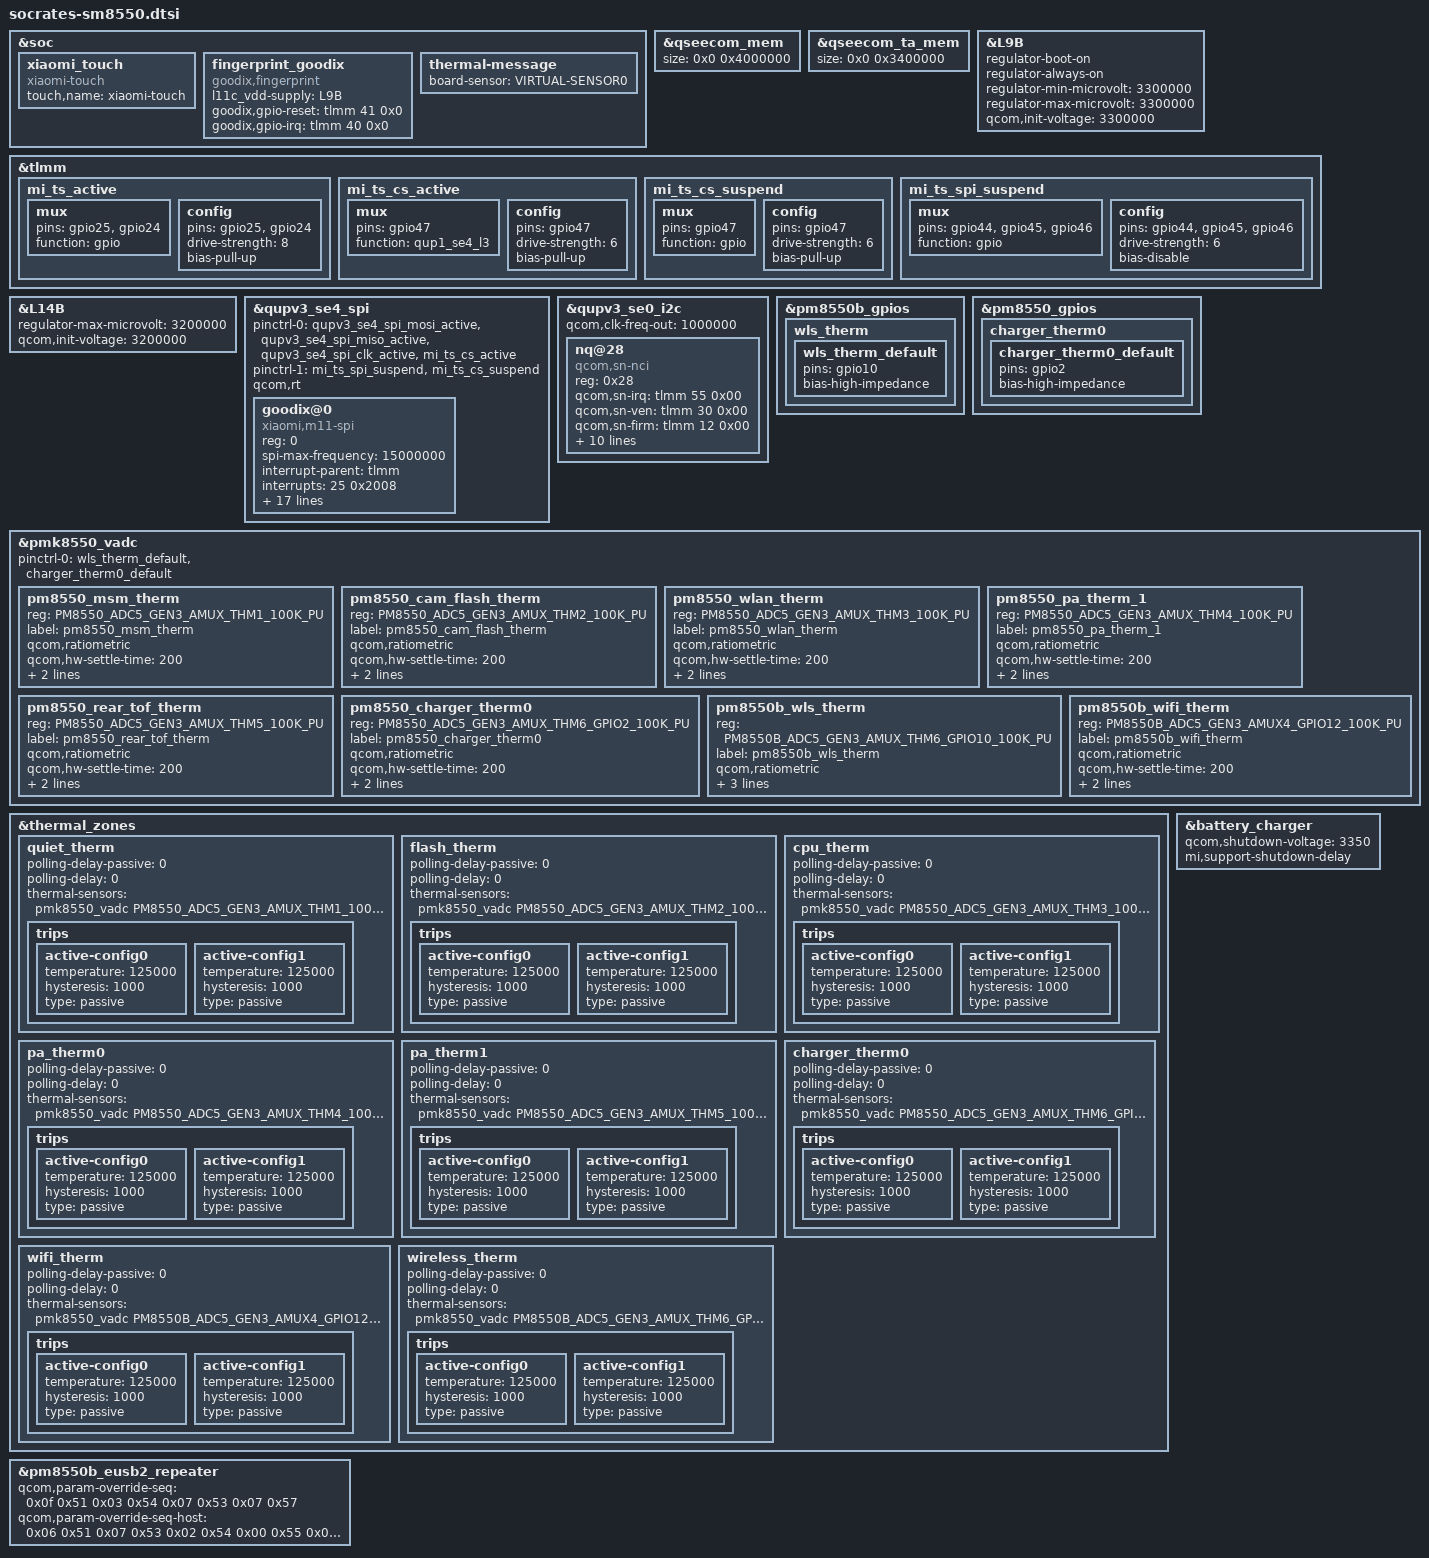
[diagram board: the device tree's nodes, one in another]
/*
  this file is for attribution only of socrates
  And public attribution of xiaomi platforms(like M2 and so and)
*/

#define SOCRATES_REGULATOR_OCP
#include "socrates-pinctrl.dtsi"
#include "xiaomi-sm8550-common.dtsi"
#include <dt-bindings/clock/qcom,rpmh.h>

&soc {
	xiaomi_touch {
		compatible = "xiaomi-touch";
		status = "ok";
		touch,name = "xiaomi-touch";
	};
	fingerprint_goodix {
		compatible = "goodix,fingerprint";
		l11c_vdd-supply = <&L9B>;
		goodix,gpio-reset = <&tlmm 41 0x0>;
		goodix,gpio-irq = <&tlmm 40 0x0>;
		status = "ok";
	};
};

&qseecom_mem {
		size = <0x0 0x4000000>;
};

&qseecom_ta_mem {
		size = <0x0 0x3400000>;
};

&L9B {
	regulator-boot-on;
	regulator-always-on;
	regulator-min-microvolt = <3300000>;
	regulator-max-microvolt = <3300000>;
	qcom,init-voltage = <3300000>;
};

&tlmm {
	mi_ts_active: mi_ts_active {
		mux {
				pins = "gpio25", "gpio24";
				function = "gpio";
		};

		config {
				pins = "gpio25", "gpio24";
				drive-strength = <8>;
				bias-pull-up;
		};
	};

	mi_ts_cs_active: mi_ts_cs_active {
		mux {
			pins = "gpio47";
			function = "qup1_se4_l3";
		};

		config {
			pins = "gpio47";
			drive-strength = <6>;
			bias-pull-up;
		};
	};

	mi_ts_cs_suspend: mi_ts_cs_suspend {
		mux {
			pins = "gpio47";
			function = "gpio";
		};

		config {
			pins = "gpio47";
			drive-strength = <6>;
			bias-pull-up;
		};
	};

	mi_ts_spi_suspend: mi_ts_spi_suspend {
		mux {
			pins = "gpio44", "gpio45", "gpio46";
			function = "gpio";
		};

		config {
			pins = "gpio44", "gpio45", "gpio46";
			drive-strength = <6>;
			bias-disable;
		};
	};
};

&L14B {
	regulator-max-microvolt = <3200000>;
	qcom,init-voltage = <3200000>;
};

&qupv3_se4_spi {
	status = "ok";
	pinctrl-0 = <&qupv3_se4_spi_mosi_active>, <&qupv3_se4_spi_miso_active>,
 						<&qupv3_se4_spi_clk_active>, <&mi_ts_cs_active>;
	pinctrl-1 = <&mi_ts_spi_suspend &mi_ts_cs_suspend>;
	qcom,rt;
	goodix@0 {
		status = "ok";
		compatible = "xiaomi,m11-spi";
		reg = <0>;
		spi-max-frequency = <15000000>;
		interrupt-parent = <&tlmm>;
		interrupts = <25 0x2008>;
		goodix,avdd-name = "avdd";
		avdd-supply = <&L14B>;
		pinctrl-names = "pmx_ts_active", "pmx_ts_suspend";
		pinctrl-0 = <&mi_ts_active>;
		pinctrl-1 = <&ts_int_suspend &ts_reset_suspend>;

		//goodix,avdd-gpio = <&tlmm 71 0x0>;
		goodix,iovdd-name = "vdd";
		vdd-supply = <&L12B>;
		goodix,irq-gpio = <&tlmm 25 0x2008>;
		goodix,reset-gpio = <&tlmm 24 0x00>;
		goodix,irq-flags = <2>;
		goodix,panel-max-x = <14400>;
		goodix,panel-max-y = <32000>;
		goodix,panel-max-w = <255>;
		goodix,panel-max-p = <4096>;
		goodix,firmware-name = "goodix_firmware_m11";
		goodix,config-name = "goodix_cfg_group_m11";
		goodix,touch-expert-array = <2 3 2 2
					     4 3 3 2
					     3 3 4 2>;
	};
};

&qupv3_se0_i2c {
	status = "ok";
	qcom,clk-freq-out = <1000000>;
	#address-cells = <1>;
	#size-cells = <0>;
	nq@28 {
		compatible = "qcom,sn-nci";
		reg = <0x28>;
		qcom,sn-irq = <&tlmm 55 0x00>;
		qcom,sn-ven = <&tlmm 30 0x00>;
		qcom,sn-firm = <&tlmm 12 0x00>;
		qcom,sn-clkreq = <&tlmm 31 0x00>;
		qcom,sn-szone = "enable";
		qcom,sn-vdd-1p8-supply = <&L15B>;
		qcom,sn-vdd-1p8-voltage = <1760000 1800000>;
		qcom,sn-vdd-1p8-current = <157000>;
		interrupt-parent = <&tlmm>;
		interrupts = <55 0>;
		interrupt-names = "nfc_irq";
		pinctrl-names = "nfc_active", "nfc_suspend";
		pinctrl-0 = <&nfc_int_active &nfc_enable_active>;
		pinctrl-1 = <&nfc_int_suspend &nfc_enable_suspend>;
		/*below clocks only need for Kailua V1 device */
		clocks = <&rpmhcc RPMH_LN_BB_CLK2>;
		clock-names = "nfc_ref_clk";
	};
};

&pm8550b_gpios {
	wls_therm {
		wls_therm_default: wls_therm_default {
		pins = "gpio10";
		bias-high-impedance;
	};
	};
};

&pm8550_gpios {
	charger_therm0 {
		charger_therm0_default: charger_therm0_default {
		pins = "gpio2";
		bias-high-impedance;
	};
	};
};

&pmk8550_vadc {
	pinctrl-names = "default";
	pinctrl-0 = <&wls_therm_default>, <&charger_therm0_default>;
	pm8550_msm_therm {
		reg = <PM8550_ADC5_GEN3_AMUX_THM1_100K_PU>;
		label = "pm8550_msm_therm";
		qcom,ratiometric;
		qcom,hw-settle-time = <200>;
		qcom,pre-scaling = <1 1>;
		qcom,adc-tm-type = <1>;
	};

	pm8550_cam_flash_therm {
		reg = <PM8550_ADC5_GEN3_AMUX_THM2_100K_PU>;
		label = "pm8550_cam_flash_therm";
		qcom,ratiometric;
		qcom,hw-settle-time = <200>;
		qcom,pre-scaling = <1 1>;
		qcom,adc-tm-type = <1>;
	};

	pm8550_wlan_therm {
		reg = <PM8550_ADC5_GEN3_AMUX_THM3_100K_PU>;
		label = "pm8550_wlan_therm";
		qcom,ratiometric;
		qcom,hw-settle-time = <200>;
		qcom,pre-scaling = <1 1>;
		qcom,adc-tm-type = <1>;
	};

	pm8550_pa_therm_1 {
		reg = <PM8550_ADC5_GEN3_AMUX_THM4_100K_PU>;
		label = "pm8550_pa_therm_1";
		qcom,ratiometric;
		qcom,hw-settle-time = <200>;
		qcom,pre-scaling = <1 1>;
		qcom,adc-tm-type = <1>;
	};

	pm8550_rear_tof_therm {
		reg = <PM8550_ADC5_GEN3_AMUX_THM5_100K_PU>;
		label = "pm8550_rear_tof_therm";
		qcom,ratiometric;
		qcom,hw-settle-time = <200>;
		qcom,pre-scaling = <1 1>;
		qcom,adc-tm-type = <1>;
	};

	pm8550_charger_therm0 {
		reg = <PM8550_ADC5_GEN3_AMUX_THM6_GPIO2_100K_PU>;
		label = "pm8550_charger_therm0";
		qcom,ratiometric;
		qcom,hw-settle-time = <200>;
		qcom,pre-scaling = <1 1>;
		qcom,adc-tm-type = <1>;
	};

	pm8550b_wls_therm {
		reg = <PM8550B_ADC5_GEN3_AMUX_THM6_GPIO10_100K_PU>;
		label = "pm8550b_wls_therm";
		qcom,ratiometric;
		qcom,hw-settle-time = <200>;
		qcom,pre-scaling = <1 1>;
		qcom,adc-tm-type = <1>;
	};

	pm8550b_wifi_therm {
		reg = <PM8550B_ADC5_GEN3_AMUX4_GPIO12_100K_PU>;
		label = "pm8550b_wifi_therm";
		qcom,ratiometric;
		qcom,hw-settle-time = <200>;
		qcom,pre-scaling = <1 1>;
		qcom,adc-tm-type = <1>;
	};
};

&thermal_zones {
	quiet_therm {
		polling-delay-passive = <0>;
		polling-delay = <0>;
		thermal-sensors = <&pmk8550_vadc PM8550_ADC5_GEN3_AMUX_THM1_100K_PU>;
		trips {
			active-config0 {
				temperature = <125000>;
				hysteresis = <1000>;
				type = "passive";
			};

			active-config1 {
				temperature = <125000>;
				hysteresis = <1000>;
				type = "passive";
			};
		};
	};

	flash_therm {
		polling-delay-passive = <0>;
		polling-delay = <0>;
		thermal-sensors = <&pmk8550_vadc PM8550_ADC5_GEN3_AMUX_THM2_100K_PU>;
		trips {
			active-config0 {
				temperature = <125000>;
				hysteresis = <1000>;
				type = "passive";
			};

			active-config1 {
				temperature = <125000>;
				hysteresis = <1000>;
				type = "passive";
			};
		};
	};

	cpu_therm {
		polling-delay-passive = <0>;
		polling-delay = <0>;
		thermal-sensors = <&pmk8550_vadc PM8550_ADC5_GEN3_AMUX_THM3_100K_PU>;
		trips {
			active-config0 {
				temperature = <125000>;
				hysteresis = <1000>;
				type = "passive";
			};

			active-config1 {
				temperature = <125000>;
				hysteresis = <1000>;
				type = "passive";
			};
		};
	};

	pa_therm0 {
		polling-delay-passive = <0>;
		polling-delay = <0>;
		thermal-sensors = <&pmk8550_vadc PM8550_ADC5_GEN3_AMUX_THM4_100K_PU>;
		trips {
			active-config0 {
				temperature = <125000>;
				hysteresis = <1000>;
				type = "passive";
			};

			active-config1 {
				temperature = <125000>;
				hysteresis = <1000>;
				type = "passive";
			};
		};
	};

	pa_therm1 {
		polling-delay-passive = <0>;
		polling-delay = <0>;
		thermal-sensors = <&pmk8550_vadc PM8550_ADC5_GEN3_AMUX_THM5_100K_PU>;
		trips {
			active-config0 {
				temperature = <125000>;
				hysteresis = <1000>;
				type = "passive";
			};

			active-config1 {
				temperature = <125000>;
				hysteresis = <1000>;
				type = "passive";
			};
		};
	};

	charger_therm0 {
		polling-delay-passive = <0>;
		polling-delay = <0>;
		thermal-sensors = <&pmk8550_vadc PM8550_ADC5_GEN3_AMUX_THM6_GPIO2_100K_PU>;
		trips {
			active-config0 {
				temperature = <125000>;
				hysteresis = <1000>;
				type = "passive";
			};

			active-config1 {
				temperature = <125000>;
				hysteresis = <1000>;
				type = "passive";
			};
		};
	};

	wifi_therm {
		polling-delay-passive = <0>;
		polling-delay = <0>;
		thermal-sensors = <&pmk8550_vadc PM8550B_ADC5_GEN3_AMUX4_GPIO12_100K_PU>;
		trips {
			active-config0 {
				temperature = <125000>;
				hysteresis = <1000>;
				type = "passive";
			};

			active-config1 {
				temperature = <125000>;
				hysteresis = <1000>;
				type = "passive";
			};
		};
	};

	wireless_therm {
		polling-delay-passive = <0>;
		polling-delay = <0>;
		thermal-sensors = <&pmk8550_vadc PM8550B_ADC5_GEN3_AMUX_THM6_GPIO10_100K_PU>;
		trips {
			active-config0 {
				temperature = <125000>;
				hysteresis = <1000>;
				type = "passive";
			};

			active-config1 {
				temperature = <125000>;
				hysteresis = <1000>;
				type = "passive";
			};
		};
	};
};

&soc {
	thermal-message {
		board-sensor = "VIRTUAL-SENSOR0";
	};
};

&pm8550b_eusb2_repeater {
       qcom,param-override-seq =
               <0x0f 0x51
                0x03 0x54
                0x07 0x53
                0x07 0x57>;
       qcom,param-override-seq-host =
                <0x06 0x51
                0x07 0x53
                0x02 0x54
                0x00 0x55
                0x04 0x57>;

};

&battery_charger {
	qcom,shutdown-voltage = <3350>;
	mi,support-shutdown-delay;
};
